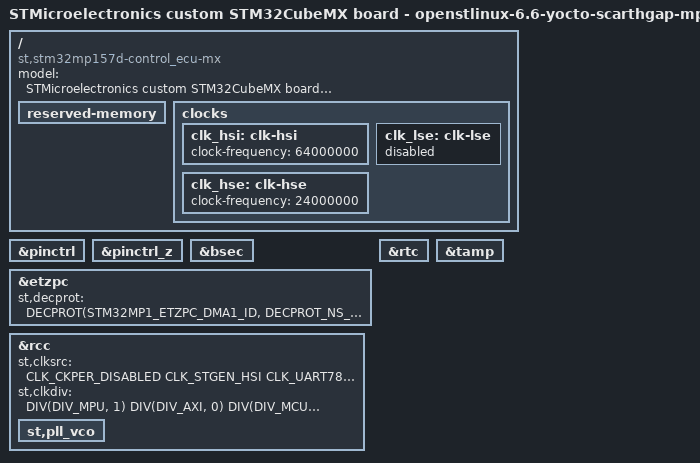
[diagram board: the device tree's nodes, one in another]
// SPDX-License-Identifier: (GPL-2.0-only OR BSD-3-Clause)
/*
 * Copyright (C) 2026, STMicroelectronics - All Rights Reserved
 * Author: STM32CubeMX code generation for STMicroelectronics.
 */

/* For more information on Device Tree configuration, please refer to
 * https://wiki.st.com/stm32mpu/wiki/Category:Device_tree_configuration
 */

/dts-v1/;

#include <dt-bindings/pinctrl/stm32-pinfunc.h>
#include <dt-bindings/clock/stm32mp1-clksrc.h>
#include <dt-bindings/soc/stm32mp15-etzpc.h>
#include "stm32mp157.dtsi"
#include "stm32mp15xd.dtsi"
#include "stm32mp15xxac-pinctrl.dtsi"

/* USER CODE BEGIN includes */
/* USER CODE END includes */

/ {
	model = "STMicroelectronics custom STM32CubeMX board - openstlinux-6.6-yocto-scarthgap-mpu-v26.06.10";
	compatible = "st,stm32mp157d-control_ecu-mx", "st,stm32mp157";

	/* !!! log : Warning - no DDR config found: 'memory' node not generated  !!! */

	/*
	memory@??? {
		reg = < ??? >;
	};
	*/

	reserved-memory {
		#address-cells = <1>;
		#size-cells = <1>;
		ranges;

		/* USER CODE BEGIN reserved-memory */
		/* USER CODE END reserved-memory */
	};

	/* USER CODE BEGIN root */
	/* USER CODE END root */

	clocks {
		/* USER CODE BEGIN clocks */
		/* USER CODE END clocks */

		clk_hsi: clk-hsi {
			clock-frequency = <64000000>;

			/* USER CODE BEGIN clk_hsi */
			/* USER CODE END clk_hsi */
		};
		clk_lse: clk-lse {
			status = "disabled";

			/* USER CODE BEGIN clk_lse */
			/* USER CODE END clk_lse */
		};
		clk_hse: clk-hse {
			clock-frequency = <24000000>;

			/* USER CODE BEGIN clk_hse */
			/* USER CODE END clk_hse */
		};
	};

}; /*root*/

/*Warning: the configuration of the secured GPIOs should be added in (addons) User Section*/
&pinctrl {
	/* USER CODE BEGIN pinctrl */
	/* USER CODE END pinctrl */
};

&pinctrl_z {
	/* USER CODE BEGIN pinctrl_z */
	/* USER CODE END pinctrl_z */
};

&bsec {
	status = "okay";

	/* USER CODE BEGIN bsec */
	/* USER CODE END bsec */
};

&etzpc {
	status = "okay";
	st,decprot = <
	/*"Non Secured" peripherals*/
	DECPROT(STM32MP1_ETZPC_DMA1_ID, DECPROT_NS_RW, DECPROT_UNLOCK)
	DECPROT(STM32MP1_ETZPC_DMAMUX_ID, DECPROT_NS_RW, DECPROT_UNLOCK)
	/*"Secured" peripherals*/
	DECPROT(STM32MP1_ETZPC_STGENC_ID, DECPROT_S_RW, DECPROT_UNLOCK)
	/*"Mcu Isolation" peripherals*/
	DECPROT(STM32MP1_ETZPC_DMA2_ID, DECPROT_MCU_ISOLATION, DECPROT_UNLOCK)
	DECPROT(STM32MP1_ETZPC_TT_FDCAN_ID, DECPROT_MCU_ISOLATION, DECPROT_UNLOCK)
	DECPROT(STM32MP1_ETZPC_TIM1_ID, DECPROT_MCU_ISOLATION, DECPROT_UNLOCK)
	DECPROT(STM32MP1_ETZPC_UART7_ID, DECPROT_MCU_ISOLATION, DECPROT_UNLOCK)

	/*Restriction: following IDs are not managed  - please to use User-Section if needed:
		  STM32MP1_ETZPC_SRAMx_ID  STM32MP1_ETZPC_RETRAM_ID  STM32MP1_ETZPC_BKPSRAM_ID*/

	/* USER CODE BEGIN etzpc_decprot */
		/*STM32CubeMX generates a basic and standard configuration for ETZPC.
		Additional device configurations can be added here if needed.
		"etzpc" node could be also overloaded in "addons" User-Section.*/
	/* USER CODE END etzpc_decprot */
	>;

	/* USER CODE BEGIN etzpc */
	/* USER CODE END etzpc */
};

&rcc {
	status = "okay";
	/* USER CODE BEGIN rcc */
	/* USER CODE END rcc */
	st,clksrc = <
		CLK_CKPER_DISABLED
		CLK_STGEN_HSI
		CLK_UART78_PCLK1
		CLK_FDCAN_HSE
		CLK_MPU_HSI
		CLK_AXI_HSI
		CLK_MCU_HSI
		CLK_RTC_LSI
		CLK_MCO1_DISABLED
		CLK_MCO2_DISABLED
	>;
	st,clkdiv = <
		DIV(DIV_MPU, 1)
		DIV(DIV_AXI, 0)
		DIV(DIV_MCU, 0)
		DIV(DIV_APB1, 0)
		DIV(DIV_APB2, 0)
		DIV(DIV_APB3, 0)
		DIV(DIV_APB4, 0)
		DIV(DIV_APB5, 0)
		DIV(DIV_RTC, 0)
		DIV(DIV_MCO1, 0)
		DIV(DIV_MCO2, 0)
	>;
	st,pll_vco {
		/* USER CODE BEGIN rcc_st-pll_vco */
		/* USER CODE END rcc_st-pll_vco */
	};

};

&rtc {
	status = "okay";

	/* USER CODE BEGIN rtc */
	/* USER CODE END rtc */
};

&tamp {
	status = "okay";

	/* USER CODE BEGIN tamp */
	/* USER CODE END tamp */
};

/* USER CODE BEGIN addons */
/* USER CODE END addons */

